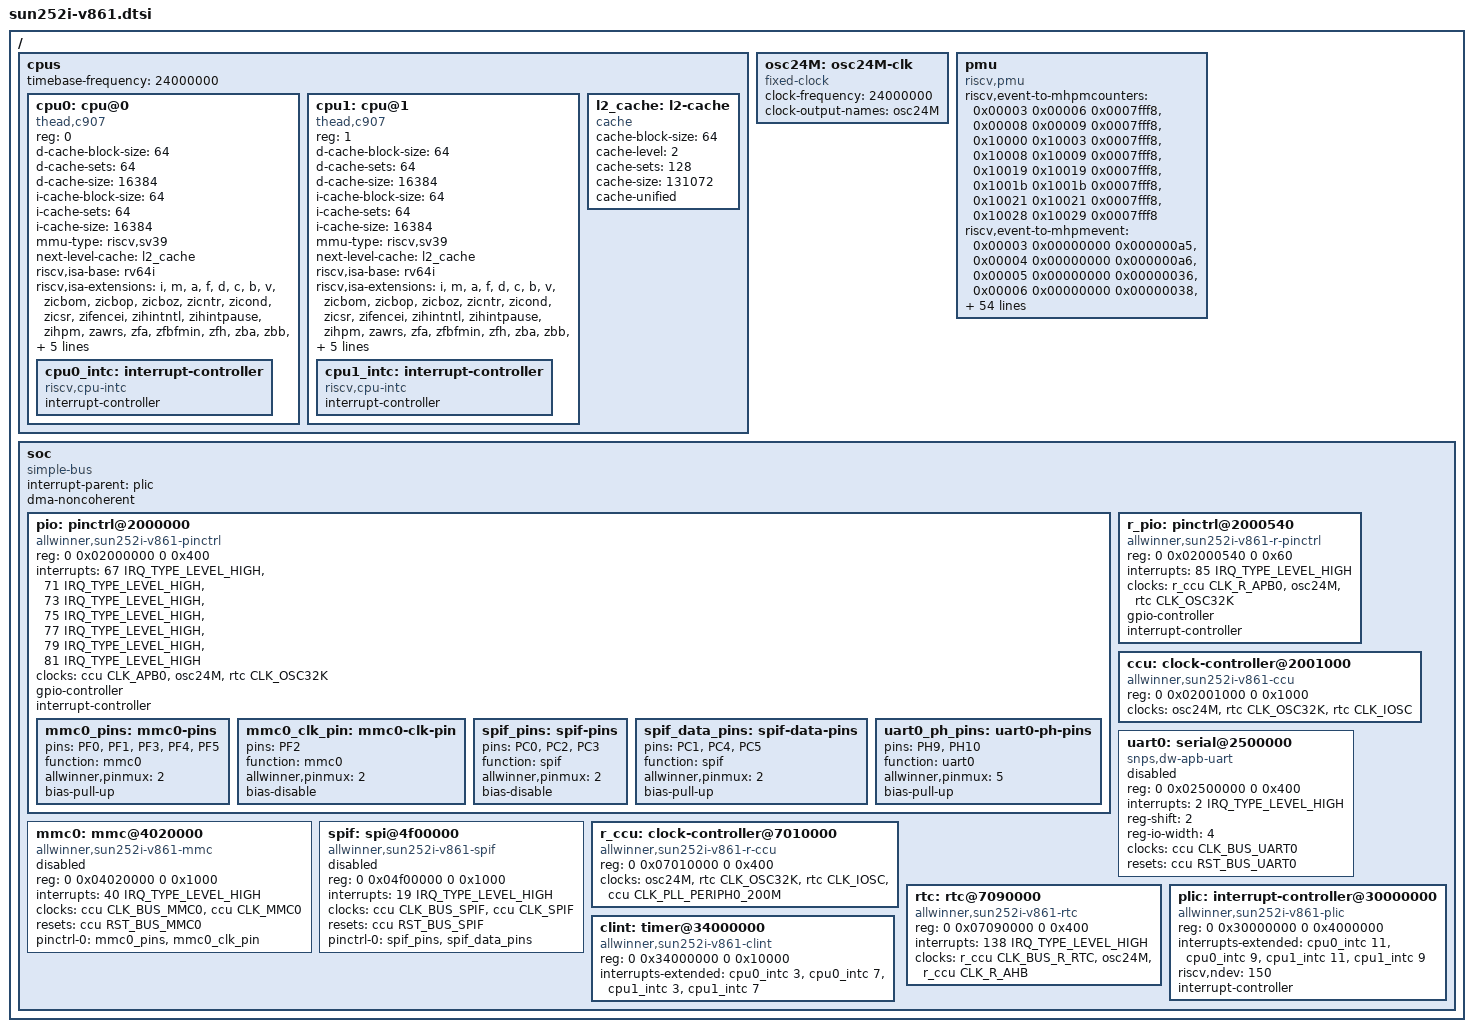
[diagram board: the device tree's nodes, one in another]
// SPDX-License-Identifier: (GPL-2.0-only OR MIT)
/* Copyright (c) 2026 Han Gao <gaohan@iscas.ac.cn> */

#include <dt-bindings/clock/sun252i-v861-ccu.h>
#include <dt-bindings/clock/sun252i-v861-r-ccu.h>
#include <dt-bindings/clock/sun6i-rtc.h>
#include <dt-bindings/interrupt-controller/irq.h>
#include <dt-bindings/reset/sun252i-v861-ccu.h>
#include <dt-bindings/reset/sun252i-v861-r-ccu.h>

/ {
	#address-cells = <2>;
	#size-cells = <2>;

	cpus {
		#address-cells = <1>;
		#size-cells = <0>;
		timebase-frequency = <24000000>;

		cpu0: cpu@0 {
			compatible = "thead,c907", "riscv";
			device_type = "cpu";
			reg = <0>;
			d-cache-block-size = <64>;
			d-cache-sets = <64>;
			d-cache-size = <16384>;
			i-cache-block-size = <64>;
			i-cache-sets = <64>;
			i-cache-size = <16384>;
			mmu-type = "riscv,sv39";
			next-level-cache = <&l2_cache>;
			riscv,isa-base = "rv64i";
			riscv,isa-extensions = "i", "m", "a", "f", "d", "c", "b", "v",
				"zicbom", "zicbop", "zicboz", "zicntr", "zicond",
				"zicsr", "zifencei", "zihintntl", "zihintpause",
				"zihpm", "zawrs", "zfa", "zfbfmin", "zfh",
				"zba", "zbb", "zbc", "zbs", "sscofpmf",
				"zvfbfmin", "zvfbfwma", "svinval", "svnapot", "svpbmt";
			riscv,cbom-block-size = <64>;
			riscv,cbop-block-size = <64>;
			riscv,cboz-block-size = <64>;

			cpu0_intc: interrupt-controller {
				compatible = "riscv,cpu-intc";
				interrupt-controller;
				#interrupt-cells = <1>;
			};
		};

		cpu1: cpu@1 {
			compatible = "thead,c907", "riscv";
			device_type = "cpu";
			reg = <1>;
			d-cache-block-size = <64>;
			d-cache-sets = <64>;
			d-cache-size = <16384>;
			i-cache-block-size = <64>;
			i-cache-sets = <64>;
			i-cache-size = <16384>;
			mmu-type = "riscv,sv39";
			next-level-cache = <&l2_cache>;
			riscv,isa-base = "rv64i";
			riscv,isa-extensions = "i", "m", "a", "f", "d", "c", "b", "v",
				"zicbom", "zicbop", "zicboz", "zicntr", "zicond",
				"zicsr", "zifencei", "zihintntl", "zihintpause",
				"zihpm", "zawrs", "zfa", "zfbfmin", "zfh",
				"zba", "zbb", "zbc", "zbs", "sscofpmf",
				"zvfbfmin", "zvfbfwma", "svinval", "svnapot", "svpbmt";
			riscv,cbom-block-size = <64>;
			riscv,cbop-block-size = <64>;
			riscv,cboz-block-size = <64>;

			cpu1_intc: interrupt-controller {
				compatible = "riscv,cpu-intc";
				interrupt-controller;
				#interrupt-cells = <1>;
			};
		};

		l2_cache: l2-cache {
			compatible = "cache";
			cache-block-size = <64>;
			cache-level = <2>;
			cache-sets = <128>;
			cache-size = <131072>;
			cache-unified;
		};
	};

	osc24M: osc24M-clk {
		compatible = "fixed-clock";
		#clock-cells = <0>;
		clock-frequency = <24000000>;
		clock-output-names = "osc24M";
	};

	pmu {
		compatible = "riscv,pmu";
		riscv,event-to-mhpmcounters =
			<0x00003 0x00006 0x0007fff8>,
			<0x00008 0x00009 0x0007fff8>,
			<0x10000 0x10003 0x0007fff8>,
			<0x10008 0x10009 0x0007fff8>,
			<0x10019 0x10019 0x0007fff8>,
			<0x1001b 0x1001b 0x0007fff8>,
			<0x10021 0x10021 0x0007fff8>,
			<0x10028 0x10029 0x0007fff8>;
		riscv,event-to-mhpmevent =
			<0x00003 0x00000000 0x000000a5>,
			<0x00004 0x00000000 0x000000a6>,
			<0x00005 0x00000000 0x00000036>,
			<0x00006 0x00000000 0x00000038>,
			<0x00008 0x00000000 0x00000027>,
			<0x00009 0x00000000 0x00000028>,
			<0x10000 0x00000000 0x0000000c>,
			<0x10001 0x00000000 0x0000000d>,
			<0x10002 0x00000000 0x0000000e>,
			<0x10003 0x00000000 0x0000000f>,
			<0x10008 0x00000000 0x00000001>,
			<0x10009 0x00000000 0x00000002>,
			<0x10019 0x00000000 0x000000a4>,
			<0x1001b 0x00000000 0x000000a3>,
			<0x10021 0x00000000 0x00000003>,
			<0x10028 0x00000000 0x00000036>,
			<0x10029 0x00000000 0x00000038>;
		riscv,raw-event-to-mhpmcounters =
			<0x00000000 0x00000001 0xffffffff 0xffffffff 0x0007fff8>,
			<0x00000000 0x00000002 0xffffffff 0xffffffff 0x0007fff8>,
			<0x00000000 0x00000003 0xffffffff 0xffffffff 0x0007fff8>,
			<0x00000000 0x00000005 0xffffffff 0xffffffff 0x0007fff8>,
			<0x00000000 0x00000006 0xffffffff 0xffffffff 0x0007fff8>,
			<0x00000000 0x00000007 0xffffffff 0xffffffff 0x0007fff8>,
			<0x00000000 0x00000008 0xffffffff 0xffffffff 0x0007fff8>,
			<0x00000000 0x00000009 0xffffffff 0xffffffff 0x0007fff8>,
			<0x00000000 0x0000000b 0xffffffff 0xffffffff 0x0007fff8>,
			<0x00000000 0x0000000c 0xffffffff 0xffffffff 0x0007fff8>,
			<0x00000000 0x0000000d 0xffffffff 0xffffffff 0x0007fff8>,
			<0x00000000 0x0000000e 0xffffffff 0xffffffff 0x0007fff8>,
			<0x00000000 0x0000000f 0xffffffff 0xffffffff 0x0007fff8>,
			<0x00000000 0x00000016 0xffffffff 0xffffffff 0x0007fff8>,
			<0x00000000 0x0000001b 0xffffffff 0xffffffff 0x0007fff8>,
			<0x00000000 0x0000001c 0xffffffff 0xffffffff 0x0007fff8>,
			<0x00000000 0x0000001d 0xffffffff 0xffffffff 0x0007fff8>,
			<0x00000000 0x0000001f 0xffffffff 0xffffffff 0x0007fff8>,
			<0x00000000 0x00000020 0xffffffff 0xffffffff 0x0007fff8>,
			<0x00000000 0x00000021 0xffffffff 0xffffffff 0x0007fff8>,
			<0x00000000 0x00000023 0xffffffff 0xffffffff 0x0007fff8>,
			<0x00000000 0x00000025 0xffffffff 0xffffffff 0x0007fff8>,
			<0x00000000 0x00000027 0xffffffff 0xffffffff 0x0007fff8>,
			<0x00000000 0x00000028 0xffffffff 0xffffffff 0x0007fff8>,
			<0x00000000 0x00000029 0xffffffff 0xffffffff 0x0007fff8>,
			<0x00000000 0x0000002a 0xffffffff 0xffffffff 0x0007fff8>,
			<0x00000000 0x00000030 0xffffffff 0xffffffff 0x0007fff8>,
			<0x00000000 0x00000036 0xffffffff 0xffffffff 0x0007fff8>,
			<0x00000000 0x00000038 0xffffffff 0xffffffff 0x0007fff8>,
			<0x00000000 0x0000009b 0xffffffff 0xffffffff 0x0007fff8>,
			<0x00000000 0x0000009c 0xffffffff 0xffffffff 0x0007fff8>,
			<0x00000000 0x0000009e 0xffffffff 0xffffffff 0x0007fff8>,
			<0x00000000 0x000000a3 0xffffffff 0xffffffff 0x0007fff8>,
			<0x00000000 0x000000a4 0xffffffff 0xffffffff 0x0007fff8>,
			<0x00000000 0x000000a5 0xffffffff 0xffffffff 0x0007fff8>,
			<0x00000000 0x000000a6 0xffffffff 0xffffffff 0x0007fff8>,
			<0x00000000 0x000000a7 0xffffffff 0xffffffff 0x0007fff8>,
			<0x00000000 0x000000a8 0xffffffff 0xffffffff 0x0007fff8>,
			<0x00000000 0x000000a9 0xffffffff 0xffffffff 0x0007fff8>,
			<0x00000000 0x000000aa 0xffffffff 0xffffffff 0x0007fff8>;
	};

	soc {
		compatible = "simple-bus";
		#address-cells = <2>;
		#size-cells = <2>;
		interrupt-parent = <&plic>;
		ranges;
		dma-noncoherent;

		pio: pinctrl@2000000 {
			compatible = "allwinner,sun252i-v861-pinctrl";
			reg = <0 0x02000000 0 0x400>;
			interrupts = <67 IRQ_TYPE_LEVEL_HIGH>, <71 IRQ_TYPE_LEVEL_HIGH>,
				     <73 IRQ_TYPE_LEVEL_HIGH>, <75 IRQ_TYPE_LEVEL_HIGH>,
				     <77 IRQ_TYPE_LEVEL_HIGH>, <79 IRQ_TYPE_LEVEL_HIGH>,
				     <81 IRQ_TYPE_LEVEL_HIGH>;
			clocks = <&ccu CLK_APB0>, <&osc24M>, <&rtc CLK_OSC32K>;
			clock-names = "apb", "hosc", "losc";
			gpio-controller;
			#gpio-cells = <3>;
			interrupt-controller;
			#interrupt-cells = <3>;

			mmc0_pins: mmc0-pins {
				pins = "PF0", "PF1", "PF3", "PF4", "PF5";
				function = "mmc0";
				allwinner,pinmux = <2>;
				bias-pull-up;
			};

			mmc0_clk_pin: mmc0-clk-pin {
				pins = "PF2";
				function = "mmc0";
				allwinner,pinmux = <2>;
				bias-disable;
			};

			spif_pins: spif-pins {
				pins = "PC0", "PC2", "PC3";
				function = "spif";
				allwinner,pinmux = <2>;
				bias-disable;
			};

			spif_data_pins: spif-data-pins {
				pins = "PC1", "PC4", "PC5";
				function = "spif";
				allwinner,pinmux = <2>;
				bias-pull-up;
			};

			uart0_ph_pins: uart0-ph-pins {
				pins = "PH9", "PH10";
				function = "uart0";
				allwinner,pinmux = <5>;
				bias-pull-up;
			};
		};

		r_pio: pinctrl@2000540 {
			compatible = "allwinner,sun252i-v861-r-pinctrl";
			reg = <0 0x02000540 0 0x60>;
			interrupts = <85 IRQ_TYPE_LEVEL_HIGH>;
			clocks = <&r_ccu CLK_R_APB0>, <&osc24M>, <&rtc CLK_OSC32K>;
			clock-names = "apb", "hosc", "losc";
			gpio-controller;
			#gpio-cells = <3>;
			interrupt-controller;
			#interrupt-cells = <3>;
		};

		ccu: clock-controller@2001000 {
			compatible = "allwinner,sun252i-v861-ccu";
			reg = <0 0x02001000 0 0x1000>;
			clocks = <&osc24M>, <&rtc CLK_OSC32K>, <&rtc CLK_IOSC>;
			clock-names = "hosc", "losc", "iosc";
			#clock-cells = <1>;
			#reset-cells = <1>;
		};

		uart0: serial@2500000 {
			compatible = "snps,dw-apb-uart";
			reg = <0 0x02500000 0 0x400>;
			interrupts = <2 IRQ_TYPE_LEVEL_HIGH>;
			reg-shift = <2>;
			reg-io-width = <4>;
			clocks = <&ccu CLK_BUS_UART0>;
			resets = <&ccu RST_BUS_UART0>;
			status = "disabled";
		};

		mmc0: mmc@4020000 {
			compatible = "allwinner,sun252i-v861-mmc";
			reg = <0 0x04020000 0 0x1000>;
			interrupts = <40 IRQ_TYPE_LEVEL_HIGH>;
			clocks = <&ccu CLK_BUS_MMC0>, <&ccu CLK_MMC0>;
			clock-names = "ahb", "mmc";
			resets = <&ccu RST_BUS_MMC0>;
			reset-names = "ahb";
			pinctrl-names = "default";
			pinctrl-0 = <&mmc0_pins>, <&mmc0_clk_pin>;
			#address-cells = <1>;
			#size-cells = <0>;
			status = "disabled";
		};

		spif: spi@4f00000 {
			compatible = "allwinner,sun252i-v861-spif";
			reg = <0 0x04f00000 0 0x1000>;
			interrupts = <19 IRQ_TYPE_LEVEL_HIGH>;
			clocks = <&ccu CLK_BUS_SPIF>, <&ccu CLK_SPIF>;
			clock-names = "ahb", "mod";
			resets = <&ccu RST_BUS_SPIF>;
			pinctrl-names = "default";
			pinctrl-0 = <&spif_pins>, <&spif_data_pins>;
			#address-cells = <1>;
			#size-cells = <0>;
			status = "disabled";
		};

		r_ccu: clock-controller@7010000 {
			compatible = "allwinner,sun252i-v861-r-ccu";
			reg = <0 0x07010000 0 0x400>;
			clocks = <&osc24M>, <&rtc CLK_OSC32K>, <&rtc CLK_IOSC>,
				 <&ccu CLK_PLL_PERIPH0_200M>;
			clock-names = "hosc", "losc", "iosc", "pll-periph";
			#clock-cells = <1>;
			#reset-cells = <1>;
		};

		rtc: rtc@7090000 {
			compatible = "allwinner,sun252i-v861-rtc",
				     "allwinner,sun50i-r329-rtc";
			reg = <0 0x07090000 0 0x400>;
			interrupts = <138 IRQ_TYPE_LEVEL_HIGH>;
			clocks = <&r_ccu CLK_BUS_R_RTC>, <&osc24M>,
				 <&r_ccu CLK_R_AHB>;
			clock-names = "bus", "hosc", "ahb";
			#clock-cells = <1>;
		};

		plic: interrupt-controller@30000000 {
			compatible = "allwinner,sun252i-v861-plic", "thead,c900-plic";
			reg = <0 0x30000000 0 0x4000000>;
			interrupts-extended = <&cpu0_intc 11>, <&cpu0_intc 9>,
					      <&cpu1_intc 11>, <&cpu1_intc 9>;
			riscv,ndev = <150>;
			interrupt-controller;
			#interrupt-cells = <2>;
			#address-cells = <0>;
		};

		clint: timer@34000000 {
			compatible = "allwinner,sun252i-v861-clint", "thead,c900-clint";
			reg = <0 0x34000000 0 0x10000>;
			interrupts-extended = <&cpu0_intc 3>, <&cpu0_intc 7>,
					      <&cpu1_intc 3>, <&cpu1_intc 7>;
		};
	};
};
